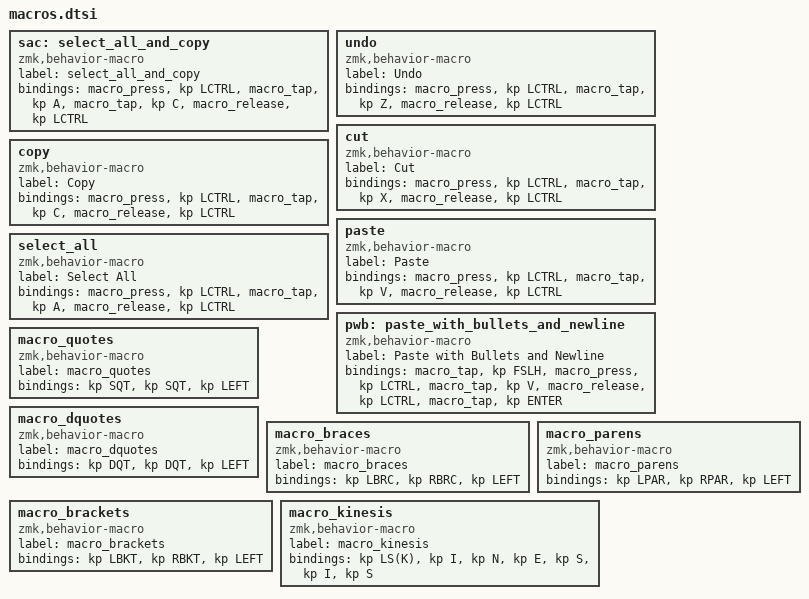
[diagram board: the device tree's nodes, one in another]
// my macros
sac: select_all_and_copy {
  label = "select_all_and_copy";
  compatible = "zmk,behavior-macro";
  #binding-cells = <0>;
  bindings
      = <&macro_press &kp LCTRL>
      , <&macro_tap &kp A>
      , <&macro_tap &kp C>
      , <&macro_release &kp LCTRL>
      ;
};

undo: undo {
  label = "Undo";
  compatible = "zmk,behavior-macro";
  #binding-cells = <0>;
  bindings
      = <&macro_press &kp LCTRL>
      , <&macro_tap &kp Z>
      , <&macro_release &kp LCTRL>
      ;
};

cut: cut {
  label = "Cut";
  compatible = "zmk,behavior-macro";
  #binding-cells = <0>;
  bindings
      = <&macro_press &kp LCTRL>
      , <&macro_tap &kp X>
      , <&macro_release &kp LCTRL>
      ;
};

copy: copy {
  label = "Copy";
  compatible = "zmk,behavior-macro";
  #binding-cells = <0>;
  bindings
      = <&macro_press &kp LCTRL>
      , <&macro_tap &kp C>
      , <&macro_release &kp LCTRL>
      ;
};

paste: paste {
  label = "Paste";
  compatible = "zmk,behavior-macro";
  #binding-cells = <0>;
  bindings
      = <&macro_press &kp LCTRL>
      , <&macro_tap &kp V>
      , <&macro_release &kp LCTRL>
      ; 
};

select_all: select_all {
  label = "Select All";
  compatible = "zmk,behavior-macro";
  #binding-cells = <0>;
  bindings
      = <&macro_press &kp LCTRL>
      , <&macro_tap &kp A>
      , <&macro_release &kp LCTRL>
      ;
};

// 「・」を入力してからペーストする。
pwb: paste_with_bullets_and_newline {
  label = "Paste with Bullets and Newline";
  compatible = "zmk,behavior-macro";
  #binding-cells = <0>;
  bindings
      = <&macro_tap &kp FSLH>
      , <&macro_press &kp LCTRL>
      , <&macro_tap &kp V>
      , <&macro_release &kp LCTRL>
      , <&macro_tap &kp ENTER>
      ;
};

// defaults
macro_quotes: macro_quotes{
compatible = "zmk,behavior-macro";
label = "macro_quotes";
#binding-cells = <0>;
bindings = <&kp SQT>, <&kp SQT>, <&kp LEFT>;
};
macro_dquotes: macro_dquotes{
compatible = "zmk,behavior-macro";
label = "macro_dquotes";
#binding-cells = <0>;
bindings = <&kp DQT>, <&kp DQT>, <&kp LEFT>;
};
macro_braces: macro_braces{
compatible = "zmk,behavior-macro";
label = "macro_braces";
#binding-cells = <0>;
bindings = <&kp LBRC>, <&kp RBRC>, <&kp LEFT>;
};
macro_parens: macro_parens{
compatible = "zmk,behavior-macro";
label = "macro_parens";
#binding-cells = <0>;
bindings = <&kp LPAR>, <&kp RPAR>, <&kp LEFT>;
};
macro_brackets: macro_brackets{
compatible = "zmk,behavior-macro";
label = "macro_brackets";
#binding-cells = <0>;
bindings = <&kp LBKT>, <&kp RBKT>, <&kp LEFT>;
};
macro_kinesis: macro_kinesis{
compatible = "zmk,behavior-macro";
label = "macro_kinesis";
#binding-cells = <0>;
bindings = <&kp LS(K)>, <&kp I>, <&kp N>, <&kp E>, <&kp S>, <&kp I>, <&kp S>;
};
